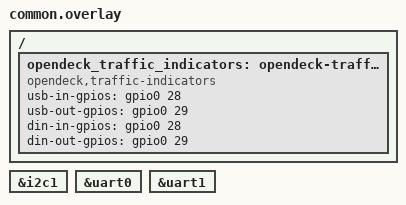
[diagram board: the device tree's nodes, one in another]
opendeck_i2c_bus: &i2c1 {};

opendeck_uart_din_midi: &uart0 {};

opendeck_uart_touchscreen: &uart1 {};

/ {
    opendeck_traffic_indicators: opendeck-traffic-indicators {
        compatible = "opendeck,traffic-indicators";
        usb-in-gpios = <&gpio0 28 GPIO_ACTIVE_HIGH>;
        usb-out-gpios = <&gpio0 29 GPIO_ACTIVE_HIGH>;
        din-in-gpios = <&gpio0 28 GPIO_ACTIVE_HIGH>;
        din-out-gpios = <&gpio0 29 GPIO_ACTIVE_HIGH>;
    };
};
